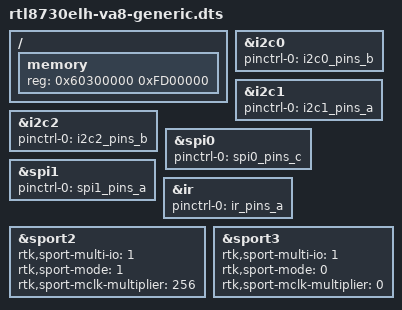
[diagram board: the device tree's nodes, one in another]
/*
 * Realtek Semiconductor Corp.
 *
 * Device Tree Structure
 */

/dts-v1/;

#include "rtl8730e.dtsi"
#include "rtl8730e-spi-nand-256m.dtsi"

/ {
	memory {
		device_type = "memory";
		// DRAM base address should be 1MB-aligned.
		reg = <0x60300000 0xFD00000>;  // 256MB -- exclude 3MB secure memory
	};
};

// Configure pinmux, avoid the pin conflict.

&i2c0{
	pinctrl-names = "default";
	pinctrl-0 = <&i2c0_pins_b>;
	status = "okay";
};

&i2c1{
	pinctrl-names = "default";
	pinctrl-0 = <&i2c1_pins_a>;
	status = "okay";
};

&i2c2{
	pinctrl-names = "default";
	pinctrl-0 = <&i2c2_pins_b>;
	status = "okay";
};

&spi0{
	pinctrl-names = "default";
	pinctrl-0 = <&spi0_pins_c>;
	status = "okay";
};

&spi1{
	pinctrl-names = "default";
	pinctrl-0 = <&spi1_pins_a>;
	status = "okay";
};

&ir{
	pinctrl-names = "default";
	pinctrl-0 = <&ir_pins_a>;
	status = "okay";
};

&sport2 {
	rtk,sport-multi-io = <1>;
	rtk,sport-mode = <1>;
	rtk,sport-mclk-multiplier = <256>;
};

&sport3 {
	rtk,sport-multi-io = <1>;
	rtk,sport-mode = <0>;
	rtk,sport-mclk-multiplier = <0>;
};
